# km_drbg_sampler: IP-XACT component
VLNV tenstorrent.com:ocah:km_drbg_sampler:1.0

## Address spaces and blocks
km_drbg_sampler_mmap.km_drbg_sampler: base 'h0, range 'h10, width 32

## Registers
Registers are 32-bit, read-only, no defined reset value unless marked. A register's access mark holds for its fields unless they carry their own. Offsets are from the block's base; lines under a group give offsets from that group; [hi:lo] are bit positions; {n}, {i} and the like mark numbered series; 'fields as' and 'values as' point back to an identical list; <NAME> marks a mode.

## km_drbg_sampler_mmap.km_drbg_sampler — DRBG random data interface and configuration/status registers
Base 0x00000000
0x00 DATA — One word of random data. Read triggers request or returns prefetch. Writes return SLVERR. No reset.
  [31:0] data — 32-bit random data from DRBG. No reset for security; power-up value undefined.
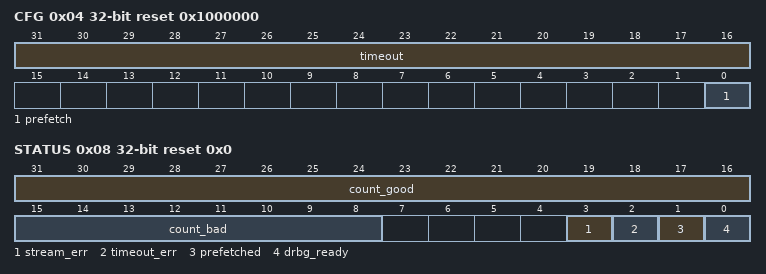
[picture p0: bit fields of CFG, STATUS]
0x04 CFG rw reset 0x1000000 — Configuration: PREFETCH enable, TIMEOUT cycles for active CPU read.
  [31:16] timeout — Cycles to wait for DRBG on active CPU read; 0 = disable. Default 256.
  [0] prefetch — Enable prefetch. When 0, prefetch data register is cleared.
0x08 STATUS access per field reset 0x0 — Status: DRBG_READY, PREFETCHED, TIMEOUT_ERR (W1C), STREAM_ERR (W1C), COUNT_BAD, COUNT_GOOD.
  [31:16] count_good rw — Counts only reads completed through ST_RESPOND, excluding prefetched words. Saturates at 0xFFFF. Writing any non-zero value clears the field to 0; writing 0 has no effect.
  [15:8] count_bad rw — Failed transactions (timeout or error). Saturates at 0xFF. Writing any non-zero value clears the field to 0; writing 0 has no effect.
  [3] stream_err rw write-1-clears — Set when there is an error on the DRBG AXI-Stream interface (e.g. TVALID deasserted before TREADY). Write 1 to clear.
  [2] timeout_err rw write-1-clears — Set when a DRBG read from the KM CPU times out. Write 1 to clear.
  [1] prefetched ro — Prefetched data available
  [0] drbg_ready ro — TVALID asserted from DRBG
0x0C PREFETCH_DATA — Prefetched word (read-only, for debugging). Cleared when PREFETCH=0. No reset; power-up undefined.
  [31:0] data — Prefetched 32-bit random data. No reset for security; power-up value undefined.

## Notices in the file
SPDX-License-Identifier: Apache-2.0
SPDX-FileCopyrightText: 2026 Tenstorrent USA, Inc.
